VERSION ""

NS_ :

BS_:

BU_: CCS AC

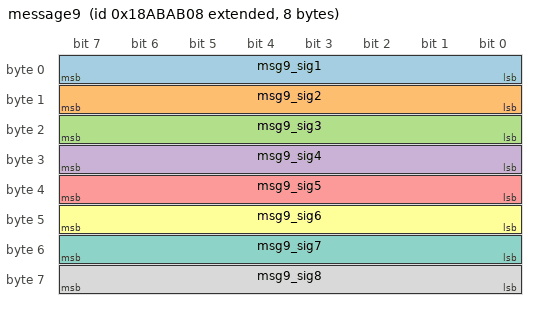
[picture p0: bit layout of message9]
BO_ 2561387272 message9: 8 Vector__XXX
 SG_ msg9_sig1 : 0|8@1+ (1,0) [0|255] "" Vector__XXX
 SG_ msg9_sig2 : 8|8@1+ (1,0) [0|255] "" Vector__XXX
 SG_ msg9_sig3 : 16|8@1+ (1,0) [0|255] "" Vector__XXX
 SG_ msg9_sig4 : 24|8@1+ (1,0) [0|255] "" Vector__XXX
 SG_ msg9_sig5 : 32|8@1+ (1,0) [0|255] "" Vector__XXX
 SG_ msg9_sig6 : 40|8@1+ (1,0) [0|255] "" Vector__XXX
 SG_ msg9_sig7 : 48|8@1+ (1,0) [0|255] "" Vector__XXX
 SG_ msg9_sig8 : 56|8@1+ (1,0) [0|255] "" Vector__XXX

BA_DEF_ SG_  "GenSigStartValue" INT 0 65535;
BA_DEF_ SG_  "GenSigSendType" ENUM  "Cyclic","OnWrite","OnWriteWithRepetition","OnChange","OnChangeWithRepetition","IfActive","IfActiveWithRepetition","NoSigSendType";
BA_DEF_ BO_  "GenMsgCycleTime" INT 0 65535;
BA_DEF_ BO_  "GenMsgSendType" ENUM  "Cyclic","Event","IfActive","CE","CA";
BA_DEF_ BO_  "GwUsedMsg" ENUM  "No","Yes";
BA_DEF_ BO_  "DiagState" ENUM  "No","Yes";
BA_DEF_ BO_  "NmMessage" ENUM  "No","Yes";
BA_DEF_  "DBName" STRING ;
BA_DEF_  "BusType" STRING ;
BA_DEF_DEF_  "GenSigStartValue" 0;
BA_DEF_DEF_  "GenSigSendType" "Cyclic";
BA_DEF_DEF_  "GenMsgCycleTime" 200;
BA_DEF_DEF_  "GenMsgSendType" "Cyclic";
BA_DEF_DEF_  "GwUsedMsg" "No";
BA_DEF_DEF_  "DiagState" "No";
BA_DEF_DEF_  "NmMessage" "No";
BA_DEF_DEF_  "DBName" "slc";
BA_DEF_DEF_  "BusType" "CAN";
BA_ "DBName" "Example";
